# RasbperryPi register map
File version: 1
Registers are 32-bit, read-write, reset 0x0 unless marked. A register's access mark holds for its fields unless they carry their own. Offsets are from the block's base; [hi:lo] are bit positions; {n}, {i} and the like mark numbered series.

## EMMC — Derived from emmc.h
Base 0x7E300000
0x00 ARG2
  [31:0] data
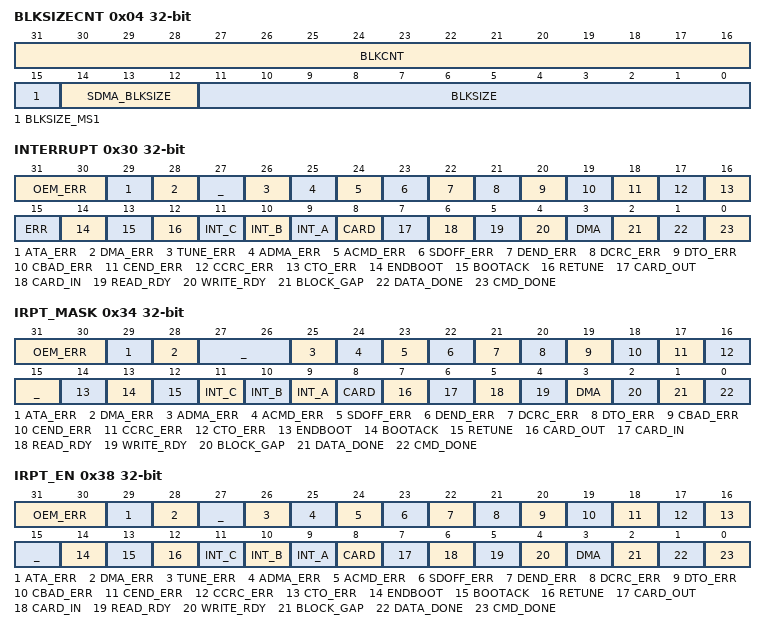
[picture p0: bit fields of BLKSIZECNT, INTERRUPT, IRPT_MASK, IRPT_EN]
0x04 BLKSIZECNT
  [31:16] BLKCNT, [15] BLKSIZE_MS1, [14:12] SDMA_BLKSIZE, [11:0] BLKSIZE
0x08 ARG1
  [31:0] data
0x0C CMDTM 30-bit
  [29:24] CMD_INDEX, [23:22] CMD_TYPE, [21] CMD_ISDATA, [20] CMD_IXCHK_EN, [19] CMD_CRCCHK_EN, [18] _, [17:16] CMD_RSPNS_TYPE, [15:6] _, [5] TM_MULTI_BLOCK, [4] TM_DAT_DIR, [3:2] TM_AUTO_CMD_EN, [1] TM_BLKCNT_EN, [0] TM_DMA_EN
{0x10+4i} RESP{i} (i=0..3)
  [31:0] data
0x20 DATA
0x24 STATUS 29-bit
  [28:25] DAT_LEVEL1, [24] CMD_LEVEL, [23:20] DAT_LEVEL0, [19] WRT_PROTECT, [18] CARD_DETECT, [17] CARD_STABLE, [16] CARD_INSERT, [15:12] _, [11] NEW_READ_DATA, [10] NEW_WRITE_DATA, [9] READ_TRANSFER, [8] WRITE_TRANSFER, [7:4] _, [3] RETUNING_REQ, [2] DAT_ACTIVE, [1] DAT_INHIBIT, [0] CMD_INHIBIT
0x28 CONTROL0 27-bit
  [26] WAKE_ONREM_EN, [25] WAKE_ONINS_EN, [24] WAKE_ONINT_EN, [23] _, [22] ALT_BOOT_EN, [21] BOOT_EN, [20] SPI_MODE, [19] GAP_IEN, [18] READWAIT_EN, [17] GAP_RESTART, [16] GAP_STOP, [15:13] _, [12] PWCTL_HWRST, [11:9] PWCTL_SDVOLTS, [8] PWCTL_ON, [7] HCTL_CRDDET_S, [6] HCTL_CRDDET, [5] HCTL_8BIT, [4:3] HCTL_DMA, [2] HCTL_HS_EN, [1] HCTL_DWIDTH, [0] HCTL_LED
0x2C CONTROL1 27-bit
  [26] SRST_DATA, [25] SRST_CMD, [24] SRST_HC, [23:20] _, [19:16] DATA_TOUNIT, [15:8] CLK_FREQ8, [7:6] CLK_FREQ_MS2, [5] CLK_GENSEL, [4:3] _, [2] CLK_EN, [1] CLK_STABLE, [0] CLK_INTLEN
0x30 INTERRUPT
  [31:30] OEM_ERR, [29] ATA_ERR, [28] DMA_ERR, [27] _, [26] TUNE_ERR, [25] ADMA_ERR, [24] ACMD_ERR, [23] SDOFF_ERR, [22] DEND_ERR, [21] DCRC_ERR, [20] DTO_ERR, [19] CBAD_ERR, [18] CEND_ERR, [17] CCRC_ERR, [16] CTO_ERR, [15] ERR, [14] ENDBOOT, [13] BOOTACK, [12] RETUNE, [11] INT_C, [10] INT_B, [9] INT_A, [8] CARD, [7] CARD_OUT, [6] CARD_IN, [5] READ_RDY, [4] WRITE_RDY, [3] DMA, [2] BLOCK_GAP, [1] DATA_DONE, [0] CMD_DONE
0x34 IRPT_MASK
  [31:30] OEM_ERR, [29] ATA_ERR, [28] DMA_ERR, [27:26] _, [25] ADMA_ERR, [24] ACMD_ERR, [23] SDOFF_ERR, [22] DEND_ERR, [21] DCRC_ERR, [20] DTO_ERR, [19] CBAD_ERR, [18] CEND_ERR, [17] CCRC_ERR, [16] CTO_ERR, [15] _, [14] ENDBOOT, [13] BOOTACK, [12] RETUNE, [11] INT_C, [10] INT_B, [9] INT_A, [8] CARD, [7] CARD_OUT, [6] CARD_IN, [5] READ_RDY, [4] WRITE_RDY, [3] DMA, [2] BLOCK_GAP, [1] DATA_DONE, [0] CMD_DONE
0x38 IRPT_EN
  [31:30] OEM_ERR, [29] ATA_ERR, [28] DMA_ERR, [27] _, [26] TUNE_ERR, [25] ADMA_ERR, [24] ACMD_ERR, [23] SDOFF_ERR, [22] DEND_ERR, [21] DCRC_ERR, [20] DTO_ERR, [19] CBAD_ERR, [18] CEND_ERR, [17] CCRC_ERR, [16] CTO_ERR, [15] _, [14] ENDBOOT, [13] BOOTACK, [12] RETUNE, [11] INT_C, [10] INT_B, [9] INT_A, [8] CARD, [7] CARD_OUT, [6] CARD_IN, [5] READ_RDY, [4] WRITE_RDY, [3] DMA, [2] BLOCK_GAP, [1] DATA_DONE, [0] CMD_DONE
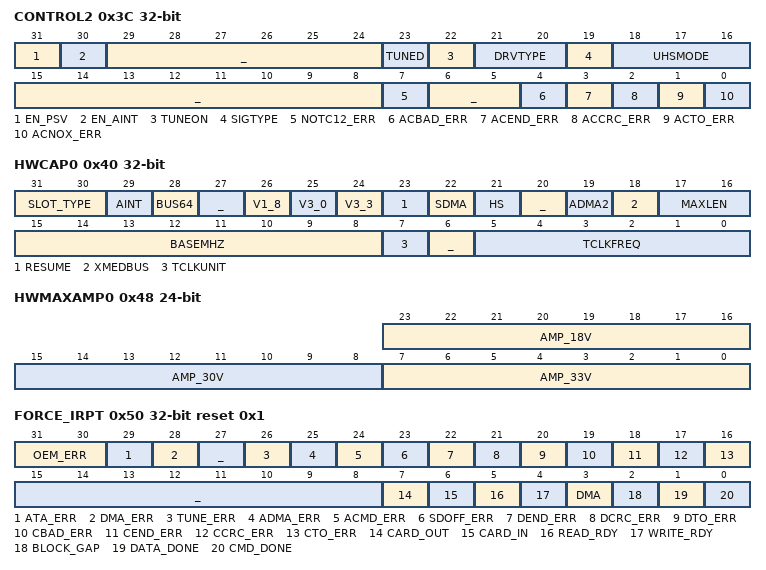
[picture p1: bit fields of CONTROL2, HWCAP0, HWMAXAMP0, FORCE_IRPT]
0x3C CONTROL2
  [31] EN_PSV, [30] EN_AINT, [29:24] _, [23] TUNED, [22] TUNEON, [21:20] DRVTYPE, [19] SIGTYPE, [18:16] UHSMODE, [15:8] _, [7] NOTC12_ERR, [6:5] _, [4] ACBAD_ERR, [3] ACEND_ERR, [2] ACCRC_ERR, [1] ACTO_ERR, [0] ACNOX_ERR
0x40 HWCAP0
  [31:30] SLOT_TYPE, [29] AINT, [28] BUS64, [27] _, [26] V1_8, [25] V3_0, [24] V3_3, [23] RESUME, [22] SDMA, [21] HS, [20] _, [19] ADMA2, [18] XMEDBUS, [17:16] MAXLEN, [15:8] BASEMHZ, [7] TCLKUNIT, [6] _, [5:0] TCLKFREQ
0x44 HWCAP1 26-bit reset 0x77
  [25] SPI_BLOCKMODE, [24] SPI_MODE, [23:16] MULTIPLIER, [15:14] DATA_RETUNE, [13] SDR50_TUNE, [12] _, [11:8] RETUNE_TMR, [7] _, [6] DRV18_TYPED, [5] DRV18_TYPEC, [4] DRV18_TYPEA, [3] _, [2] DDR50, [1] SDR104, [0] SDR50
0x48 HWMAXAMP0 24-bit
  [23:16] AMP_18V, [15:8] AMP_30V, [7:0] AMP_33V
0x50 FORCE_IRPT reset 0x1
  [31:30] OEM_ERR, [29] ATA_ERR, [28] DMA_ERR, [27] _, [26] TUNE_ERR, [25] ADMA_ERR, [24] ACMD_ERR, [23] SDOFF_ERR, [22] DEND_ERR, [21] DCRC_ERR, [20] DTO_ERR, [19] CBAD_ERR, [18] CEND_ERR, [17] CCRC_ERR, [16] CTO_ERR, [15:8] _, [7] CARD_OUT, [6] CARD_IN, [5] READ_RDY, [4] WRITE_RDY, [3] DMA, [2] BLOCK_GAP, [1] DATA_DONE, [0] CMD_DONE
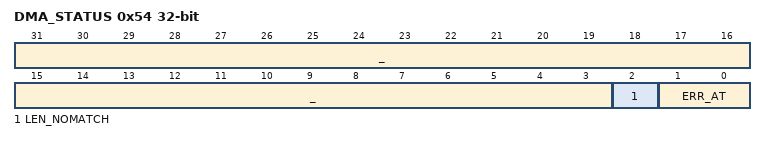
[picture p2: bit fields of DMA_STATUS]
0x54 DMA_STATUS
  [31:3] _, [2] LEN_NOMATCH, [1:0] ERR_AT
0x70 BOOT_TIMEOUT
0x74 DBG_SEL 1-bit
  [0] SELECT
0x80 EXRDFIFO_CFG 3-bit
  [2:0] RD_THRSH
0x84 EXRDFIFO_EN 1-bit
  [0] ENABLE
0x88 TUNE_STEP 3-bit
  [2:0] DELAY
